# R7FA4L1BD register map
Vendor: Renesas Electronics Corporation; Series: RA4; File version: 1.20.03
CPU: CM33 r0p4, little endian, MPU, FPU, VTOR, 4 interrupt priority bits, 96 interrupts
Registers are 32-bit, read-write, reset 0x0 unless marked. A register's access mark holds for its fields unless they carry their own. Offsets are from the block's base; [hi:lo] are bit positions.

## ECCMB
Base 0x4012F000
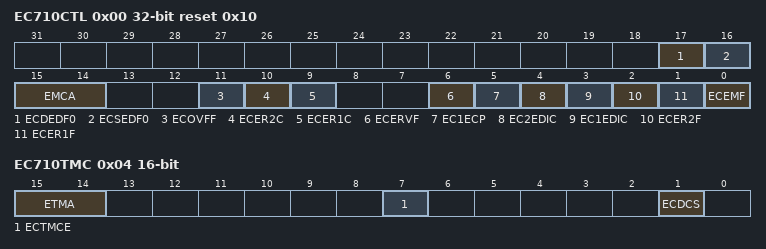
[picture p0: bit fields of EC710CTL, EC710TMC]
0x00 EC710CTL reset 0x10 — ECC Control Register
  [17] ECDEDF0 ro — 2-bit ECC Error Address Detection Flag
    0=2-bit error has not occurred after reset or clearing ECER2F bit; 1=2-bit error has occurred and the address was captured
  [16] ECSEDF0 ro — 1-bit ECC Error Address Detection Flag
    0=1-bit error has not occurred after reset or clearing ECER1F bit; 1=1-bit error has occurred and the address was captured
  [15:14] EMCA — ECC Error Detection Enable Access Control
    1=Can write ECC Error Detection Control (ECERVF) bit; other=Others (Cannot write ECERVF bit)
  [11] ECOVFF ro — ECC Overflow Detection Flag
    0=No clear flag; 1=Clear flag
  [10] ECER2C — 2-bit ECC Error Detection Flag Clear
    0=No clear flag; 1=Clear 2-bit ECC error detection flag
  [9] ECER1C — Accumulating ECC Error Detection and Correction Flag Clear
    0=No clear flag; 1=Clear accumulating ECC error detection and correction flag
  [6] ECERVF — ECC Error Detection Enable
    0=Disable error detection; 1=Enable error detection
  [5] EC1ECP — 1-bit ECC Error Correction Permission
    0=Enable error correction at 1-bit error detection; 1=Disable error correction at 1-bit error detection
  [4] EC2EDIC — 2-bit ECC Error Detection Interrupt Control
    0=Disable 2-bit error detection interrupt request; 1=Enable 2-bit error detection interrupt request
  [3] EC1EDIC — 1-bit ECC Error Detection Interrupt Control
    0=Disable 1-bit error detection interrupt request; 1=Enable 1-bit error detection interrupt request
  [2] ECER2F ro — 2-bit ECC Error Detection Flag
    0=After clearing this bit, 2-bit error has not detected; 1=2-bit error has detected
  [1] ECER1F ro — 1-bit ECC Error Detection and Correction Flag
    0=After clearing this bit, 1-bit error correction has not detected and corrected; 1=1-bit error has detected and corrected
  [0] ECEMF ro — ECC Error Message Flag
    0=There is no bit error in the present RAM output data; 1=There is a bit error in the present RAM output data
0x04 EC710TMC 16-bit — ECC Test Mode Control Register
  [15:14] ETMA — ECC Test Mode Bit Access Control
  [7] ECTMCE — ECC Test Mode Control Enable
    0=The access to test mode register and bit is disabled; 1=The access to test mode register and bit is enabled
  [1] ECDCS — ECC Decode Input Select
    0=Input lower 32 bits of RAM output data to data area of decode circuit; 1=Input ECEDB31-0 in EC710TED register to data area of decode circuit
0x0C EC710TED — ECC Test Substitute Data Register
  [31:0] ECEDB — ECC Test Substitute Data
0x10 EC710EAD0 ro — ECC Error Address Register
  [9:0] ECEAD — ECC Error Address

## GPT_OPS — Output Phase Switching Controller
Base 0x40169A00
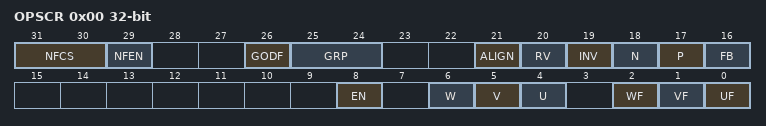
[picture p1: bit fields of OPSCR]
0x00 OPSCR — Output Phase Switching Control Register
  [31:30] NFCS — External Input Noise Filter Clock Selection
    0=PCLKD/1; 1=PCLKD/4; 2=PCLKD/16; 3=PCLKD/64
  [29] NFEN — External Input Noise Filter Enable
    0=Do not use a noise filter on the external input; 1=Use a noise filter on the external input
  [26] GODF — Group Output Disable Function
    0=This bit function is ignored; 1=Group disable clears the OPSCR.EN bit
  [25:24] GRP — Output Disabled Source Selection
  [21] ALIGN — Input Phase Alignment
    0=Input phase aligned to PCLKD; 1=Input phase aligned to the falling edge of PWM
  [20] RV — Output Phase Rotation Direction Reversal Control
    0=Positive rotation; 1=Reverse rotation
  [19] INV — Output Phase Invert Control
    0=Positive logic (active-high) output; 1=Negative logic (active-low) output
  [18] N — Negative-Phase Output (N) Control
    0=Level signal output; 1=PWM signal output
  [17] P — Positive-Phase Output (P) Control
    0=Level signal output; 1=PWM signal output
  [16] FB — External Feedback Signal Enable
    0=Select the external input; 1=Select the soft setting (OPSCR.UF, VF, WF)
  [8] EN — Output Phase Enable
    0=Do not output (Hi-Z external pin); 1=Output
  [6] W ro — Input W-Phase Monitor
  [5] V ro — Input V-Phase Monitor
  [4] U ro — Input U-Phase Monitor
  [2] WF
  [1] VF
  [0] UF

## DAC12 — 12-bit D/A converter
Base 0x40171000
0x00 DADR0 16-bit — D/A Data Register 0
0x04 DACR 8-bit reset 0x1F — D/A Control Register
  [6] DAOE0 — D/A Output Enable 0
    0=Disable analog output of channel 0 (DA0); 1=Enable D/A conversion of channel 0 (DA0)
0x05 DADPR 8-bit — DADR0 Format Select Register
  [7] DPSEL — DADR0 Format Select
    0=Right-justified format; 1=Left-justified format
0x06 DAADSCR 8-bit — D/A A/D Synchronous Start Control Register
  [7] DAADST — D/A A/D Synchronous Conversion
    0=Do not synchronize DAC12 with ADC12 operation (disable interference reduction between D/A and A/D conversion); 1=Synchronize DAC12 with ADC12 operation (enable interference reduction between D/A and A/D conversion)
0x07 DAVREFCR 8-bit — D/A VREF Control Register
  [0] REF — D/A Reference Voltage Select
    0=No reference voltage selected; 1=AVCC0/AVSS0 selected

## FLCN — Flash I/O Registers
Base 0x407EC000
0x90 DFLCTL 8-bit — Data Flash Control Register
  [0] DFLEN — Data Flash Access Enable
    0=Access to the data flash is disabled; 1=Access to the data flash is enabled
0x228 TSCDR 16-bit ro reset not defined — Temperature Sensor Calibration Data Register
0x3FC4 FLDWAITR 8-bit — Memory Wait Cycle Control Register for Data Flash
  [0] FLDWAIT1 — Memory Wait Cycle Select for Data Flash
    0=One wait access (default); 1=Two wait accesses
0x3FC8 PFBER 8-bit — Prefetch Buffer Enable Register
  [0] PFBE — Prefetch Buffer Enable bit
    0=Prefetch buffer is disabled; 1=Prefetch buffer is enabled

## CIBC — Code Flash
Base 0x407EC200
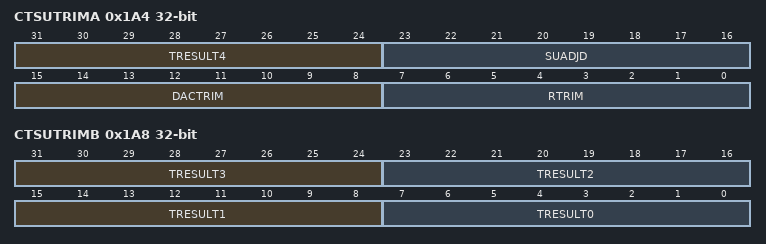
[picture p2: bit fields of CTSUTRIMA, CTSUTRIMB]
0x1A4 CTSUTRIMA reset not defined — CTSU Trimming Register A
  [31:24] TRESULT4 — Coefficient of variation for the reference load resistance
  [23:16] SUADJD — CTSU SUCLK Frequency Adjustment
  [15:8] DACTRIM — Linearity Adjustment of Offset Current
  [7:0] RTRIM — CTSU Reference Resistance Adjustment
0x1A8 CTSUTRIMB reset not defined — CTSU Trimming Register B
  [31:24] TRESULT3 — The coefficient of variation for the 60 kΩ reference load resistance is stored.
  [23:16] TRESULT2 — The coefficient of variation for the 30 kΩ reference load resistance is stored.
  [15:8] TRESULT1 — The coefficient of variation for the 15 kΩ reference load resistance is stored.
  [7:0] TRESULT0 — The coefficient of variation for the 7.5 kΩ reference load resistance is stored.

## CPU_OCD — OCD Function
Base 0x80000000
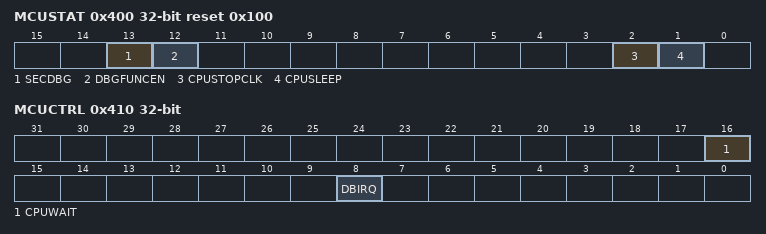
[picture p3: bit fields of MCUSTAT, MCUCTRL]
0x400 MCUSTAT ro reset 0x100 (reset mask 0xFFFFCFF9) — MCU Status Register
  [13] SECDBG — Secure Debug status
    0=Secure Debug is not available; 1=Secure Debug is available
  [12] DBGFUNCEN — Debugger status
    0=Debugger connection is not available; 1=Debugger function is enabled
  [2] CPUSTOPCLK — CPU clock status
    0=CPU clock is not stopped; 1=CPU clock is stopped
  [1] CPUSLEEP — Sleep mode status
    0=CPU is not in Sleep mode; 1=CPU in Sleep mode
0x410 MCUCTRL — MCU Control Register
  [16] CPUWAIT — CPU Wait Setting
    0=Clear CPUWAIT to low; 1=Set CPUWAIT to high
  [8] DBIRQ — Debug Interrupt Request
    0=Debug interrupt not requested; 1=Debug interrupt requested
